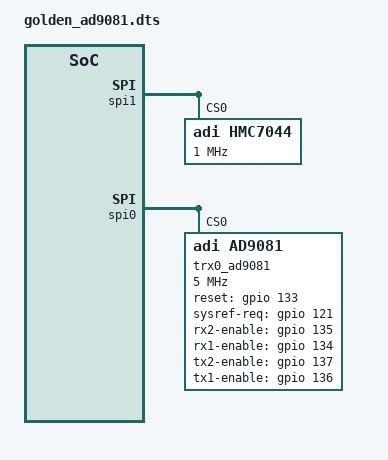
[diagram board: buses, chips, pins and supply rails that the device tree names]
	&axi_mxfe_rx_jesd_rx_axi {
		/delete-property/ compatible;
		/delete-property/ clocks;
		/delete-property/ clock-names;
		/delete-property/ #clock-cells;
		/delete-property/ adi,octets-per-frame;
		/delete-property/ adi,frames-per-multiframe;
		#clock-cells = <0>;
		#jesd204-cells = <2>;
		jesd204-device;
		clocks = <&zynqmp_clk 71>, <&hmc7044 10>, <&axi_mxfe_rx_xcvr 0>;
		clock-names = "s_axi_aclk", "device_clk", "lane_clk";
		jesd204-inputs = <&axi_mxfe_rx_xcvr 0 2>;
		compatible = "adi,axi-jesd204-rx-1.0";
		adi,octets-per-frame = <2>;
		adi,frames-per-multiframe = <32>;
	};
	&axi_mxfe_tx_jesd_tx_axi {
		/delete-property/ compatible;
		/delete-property/ clocks;
		/delete-property/ clock-names;
		/delete-property/ #clock-cells;
		/delete-property/ adi,octets-per-frame;
		/delete-property/ adi,frames-per-multiframe;
		#clock-cells = <0>;
		#jesd204-cells = <2>;
		jesd204-device;
		clocks = <&zynqmp_clk 71>, <&hmc7044 6>, <&axi_mxfe_tx_xcvr 0>;
		clock-names = "s_axi_aclk", "device_clk", "lane_clk";
		jesd204-inputs = <&axi_mxfe_tx_xcvr 0 0>;
		compatible = "adi,axi-jesd204-tx-1.0";
		adi,octets-per-frame = <2>;
		adi,frames-per-multiframe = <32>;
	};
	&spi1 {
		status = "okay";
		#address-cells = <1>;
		#size-cells = <0>;
		hmc7044: hmc7044@0 {
			compatible = "adi,hmc7044";
			#address-cells = <1>;
			#size-cells = <0>;
			#clock-cells = <1>;
			#jesd204-cells = <2>;
			jesd204-device;
			reg = <0>;
			adi,gpi-controls = <0x00 0x00 0x00 0x00>;
			adi,gpo-controls = <0x37 0x33 0x00 0x00>;
			spi-max-frequency = <1000000>;
			adi,pll1-clkin-frequencies = <122880000 10000000 0 0>;
			adi,pll1-ref-prio-ctrl = <0xE1>;
			adi,pll1-ref-autorevert-enable;
			adi,pll1-loop-bandwidth-hz = <200>;
			adi,pll1-charge-pump-current-ua = <720>;
			adi,pfd1-maximum-limit-frequency-hz = <1000000>;
			adi,vcxo-frequency = <122880000>;
			adi,pll2-output-frequency = <3000000000>;
			adi,sysref-timer-divider = <1024>;
			adi,pulse-generator-mode = <0>;
			jesd204-sysref-provider;
			adi,jesd204-max-sysref-frequency-hz = <2000000>;
			adi,clkin0-buffer-mode = <0x07>;
			adi,clkin1-buffer-mode = <0x07>;
			adi,oscin-buffer-mode = <0x15>;
			clock-output-names = "hmc7044_out0", "hmc7044_out1", "hmc7044_out2", "hmc7044_out3", "hmc7044_out4", "hmc7044_out5", "hmc7044_out6", "hmc7044_out7", "hmc7044_out8", "hmc7044_out9", "hmc7044_out10", "hmc7044_out11", "hmc7044_out12", "hmc7044_out13";
			hmc7044_c0: channel@0 {
				reg = <0>;
				adi,extended-name = "CORE_CLK_RX";
				adi,divider = <12>;
				adi,driver-mode = <2>;
			};
			hmc7044_c2: channel@2 {
				reg = <2>;
				adi,extended-name = "DEV_REFCLK";
				adi,divider = <12>;
				adi,driver-mode = <2>;
			};
			hmc7044_c3: channel@3 {
				reg = <3>;
				adi,extended-name = "DEV_SYSREF";
				adi,divider = <1536>;
				adi,driver-mode = <2>;
				adi,jesd204-sysref-chan;
			};
			hmc7044_c6: channel@6 {
				reg = <6>;
				adi,extended-name = "CORE_CLK_TX";
				adi,divider = <12>;
				adi,driver-mode = <2>;
			};
			hmc7044_c8: channel@8 {
				reg = <8>;
				adi,extended-name = "FPGA_REFCLK1";
				adi,divider = <6>;
				adi,driver-mode = <2>;
			};
			hmc7044_c10: channel@10 {
				reg = <10>;
				adi,extended-name = "CORE_CLK_RX_ALT";
				adi,divider = <12>;
				adi,driver-mode = <2>;
			};
			hmc7044_c12: channel@12 {
				reg = <12>;
				adi,extended-name = "FPGA_REFCLK2";
				adi,divider = <6>;
				adi,driver-mode = <2>;
			};
			hmc7044_c13: channel@13 {
				reg = <13>;
				adi,extended-name = "FPGA_SYSREF";
				adi,divider = <1536>;
				adi,driver-mode = <2>;
				adi,jesd204-sysref-chan;
			};
		};
	};
	&spi0 {
		status = "okay";
		#address-cells = <1>;
		#size-cells = <0>;
		trx0_ad9081: ad9081@0 {
			compatible = "adi,ad9081";
			#clock-cells = <1>;
			clock-output-names = "rx_sampl_clk", "tx_sampl_clk";
			#jesd204-cells = <2>;
			jesd204-top-device = <0>;
			jesd204-device;
			reg = <0>;
			reset-gpios = <&gpio 133 0>;
			sysref-req-gpios = <&gpio 121 0>;
			rx2-enable-gpios = <&gpio 135 0>;
			rx1-enable-gpios = <&gpio 134 0>;
			tx2-enable-gpios = <&gpio 137 0>;
			tx1-enable-gpios = <&gpio 136 0>;
			clocks = <&hmc7044 2>;
			clock-names = "dev_clk";
			jesd204-link-ids = <2 0>;
			jesd204-inputs = <&rx_mxfe_tpl_core_adc_tpl_core 0 2>, <&tx_mxfe_tpl_core_dac_tpl_core 0 0>;
			spi-max-frequency = <5000000>;
			adi,tx-dacs {
				#size-cells = <0>;
				#address-cells = <1>;
				adi,dac-frequency-hz = /bits/ 64 <12000000000>;
				adi,main-data-paths {
					#address-cells = <1>;
					#size-cells = <0>;
					adi,interpolation = <8>;
					dac@0 { reg = <0>; };
					dac@1 { reg = <1>; };
					dac@2 { reg = <2>; };
					dac@3 { reg = <3>; };
				};
				adi,channelizer-paths {
					#address-cells = <1>;
					#size-cells = <0>;
					adi,interpolation = <6>;
					ad9081_tx_fddc_chan0: channel@0 { reg = <0>; };
					ad9081_tx_fddc_chan1: channel@1 { reg = <1>; };
					ad9081_tx_fddc_chan2: channel@2 { reg = <2>; };
					ad9081_tx_fddc_chan3: channel@3 { reg = <3>; };
					ad9081_tx_fddc_chan4: channel@4 { reg = <4>; };
					ad9081_tx_fddc_chan5: channel@5 { reg = <5>; };
					ad9081_tx_fddc_chan6: channel@6 { reg = <6>; };
					ad9081_tx_fddc_chan7: channel@7 { reg = <7>; };
				};
				adi,jesd-links {
					#size-cells = <0>;
					#address-cells = <1>;
					link@0 {
						reg = <0>;
						adi,converter-select = <&ad9081_tx_fddc_chan0 0>, <&ad9081_tx_fddc_chan0 1>, <&ad9081_tx_fddc_chan1 0>, <&ad9081_tx_fddc_chan1 1>, <&ad9081_tx_fddc_chan2 0>, <&ad9081_tx_fddc_chan2 1>, <&ad9081_tx_fddc_chan3 0>, <&ad9081_tx_fddc_chan3 1>;
						adi,logical-lane-mapping = /bits/ 8 <0 2 7 7 1 7 7 3>;
						adi,link-mode = <9>;
						adi,subclass = <1>;
						adi,version = <1>;
						adi,dual-link = <0>;
						adi,converters-per-device = <8>;
						adi,octets-per-frame = <2>;
						adi,frames-per-multiframe = <32>;
						adi,converter-resolution = <16>;
						adi,bits-per-sample = <16>;
						adi,control-bits-per-sample = <0>;
						adi,lanes-per-device = <4>;
						adi,samples-per-converter-per-frame = <1>;
						adi,high-density = <0>;
					};
				};
			};
			adi,rx-adcs {
				#size-cells = <0>;
				#address-cells = <1>;
				adi,adc-frequency-hz = /bits/ 64 <4000000000>;
				adi,main-data-paths {
					#address-cells = <1>;
					#size-cells = <0>;
					adc@0 { reg = <0>; adi,decimation = <4>; };
					adc@1 { reg = <1>; adi,decimation = <4>; };
					adc@2 { reg = <2>; adi,decimation = <4>; };
					adc@3 { reg = <3>; adi,decimation = <4>; };
				};
				adi,channelizer-paths {
					#address-cells = <1>;
					#size-cells = <0>;
					ad9081_rx_fddc_chan0: channel@0 { reg = <0>; adi,decimation = <4>; };
					ad9081_rx_fddc_chan1: channel@1 { reg = <1>; adi,decimation = <4>; };
					ad9081_rx_fddc_chan2: channel@2 { reg = <2>; adi,decimation = <4>; };
					ad9081_rx_fddc_chan3: channel@3 { reg = <3>; adi,decimation = <4>; };
					ad9081_rx_fddc_chan4: channel@4 { reg = <4>; adi,decimation = <4>; };
					ad9081_rx_fddc_chan5: channel@5 { reg = <5>; adi,decimation = <4>; };
					ad9081_rx_fddc_chan6: channel@6 { reg = <6>; adi,decimation = <4>; };
					ad9081_rx_fddc_chan7: channel@7 { reg = <7>; adi,decimation = <4>; };
				};
				adi,jesd-links {
					#size-cells = <0>;
					#address-cells = <1>;
					link@0 {
						reg = <0>;
						adi,converter-select = <&ad9081_rx_fddc_chan0 0>, <&ad9081_rx_fddc_chan0 1>, <&ad9081_rx_fddc_chan1 0>, <&ad9081_rx_fddc_chan1 1>, <&ad9081_rx_fddc_chan2 0>, <&ad9081_rx_fddc_chan2 1>, <&ad9081_rx_fddc_chan3 0>, <&ad9081_rx_fddc_chan3 1>;
						adi,logical-lane-mapping = /bits/ 8 <2 0 7 7 7 7 3 1>;
						adi,link-mode = <10>;
						adi,subclass = <1>;
						adi,version = <1>;
						adi,dual-link = <0>;
						adi,converters-per-device = <8>;
						adi,octets-per-frame = <2>;
						adi,frames-per-multiframe = <32>;
						adi,converter-resolution = <16>;
						adi,bits-per-sample = <16>;
						adi,control-bits-per-sample = <0>;
						adi,lanes-per-device = <4>;
						adi,samples-per-converter-per-frame = <1>;
						adi,high-density = <0>;
					};
				};
			};
		};
	};
	&axi_mxfe_rx_dma {
		/delete-property/ compatible;
		compatible = "adi,axi-dmac-1.00.a";
		#dma-cells = <1>;
		#clock-cells = <0>;
	};
	&rx_mxfe_tpl_core_adc_tpl_core {
		/delete-property/ compatible;
		/delete-property/ clocks;
		/delete-property/ clock-names;
		#jesd204-cells = <2>;
		jesd204-device;
		dmas = <&axi_mxfe_rx_dma 0>;
		dma-names = "rx";
		spibus-connected = <&trx0_ad9081>;
		jesd204-inputs = <&axi_mxfe_rx_jesd_rx_axi 0 2>;
		compatible = "adi,axi-ad9081-rx-1.0";
	};
	&axi_mxfe_rx_xcvr {
		/delete-property/ compatible;
		/delete-property/ clocks;
		/delete-property/ clock-names;
		/delete-property/ #clock-cells;
		/delete-property/ clock-output-names;
		/delete-property/ adi,sys-clk-select;
		/delete-property/ adi,out-clk-select;
		compatible = "adi,axi-adxcvr-1.0";
		#clock-cells = <1>;
		#jesd204-cells = <2>;
		jesd204-device;
		clocks = <&hmc7044 12>;
		clock-names = "conv";
		clock-output-names = "rx_gt_clk", "rx_out_clk";
		jesd204-inputs = <&hmc7044 0 2>;
		adi,sys-clk-select = <3>;
		adi,out-clk-select = <4>;
		adi,use-lpm-enable;
	};
	&axi_mxfe_tx_dma {
		/delete-property/ compatible;
		compatible = "adi,axi-dmac-1.00.a";
		#dma-cells = <1>;
		#clock-cells = <0>;
	};
	&tx_mxfe_tpl_core_dac_tpl_core {
		/delete-property/ compatible;
		/delete-property/ clocks;
		/delete-property/ clock-names;
		#jesd204-cells = <2>;
		jesd204-device;
		dmas = <&axi_mxfe_tx_dma 0>;
		dma-names = "tx";
		clocks = <&trx0_ad9081 1>;
		clock-names = "sampl_clk";
		spibus-connected = <&trx0_ad9081>;
		jesd204-inputs = <&axi_mxfe_tx_jesd_tx_axi 0 0>;
		compatible = "adi,axi-ad9081-tx-1.0";
	};
	&axi_mxfe_tx_xcvr {
		/delete-property/ compatible;
		/delete-property/ clocks;
		/delete-property/ clock-names;
		/delete-property/ #clock-cells;
		/delete-property/ clock-output-names;
		/delete-property/ adi,sys-clk-select;
		/delete-property/ adi,out-clk-select;
		compatible = "adi,axi-adxcvr-1.0";
		#clock-cells = <1>;
		#jesd204-cells = <2>;
		jesd204-device;
		clocks = <&hmc7044 12>;
		clock-names = "conv";
		clock-output-names = "tx_gt_clk", "tx_out_clk";
		jesd204-inputs = <&hmc7044 0 0>;
		adi,sys-clk-select = <3>;
		adi,out-clk-select = <4>;
	};
